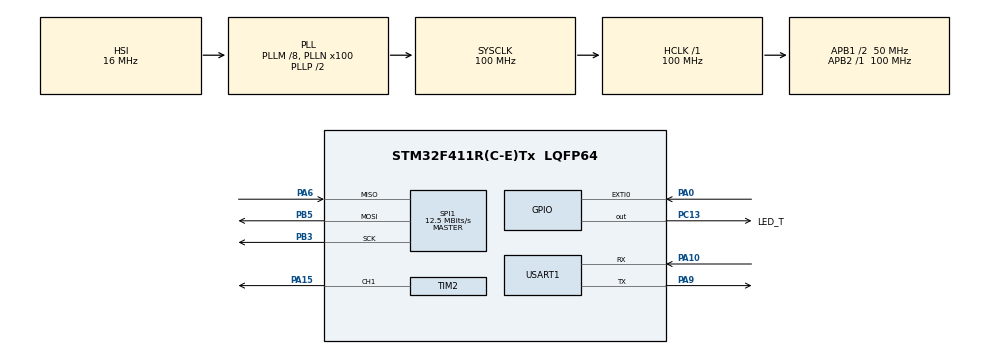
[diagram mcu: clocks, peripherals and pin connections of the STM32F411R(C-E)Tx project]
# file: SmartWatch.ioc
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Dma.Request0=USART1_RX
Dma.Request1=SPI1_TX
Dma.SPI1_TX.1.Direction=DMA_MEMORY_TO_PERIPH
Dma.SPI1_TX.1.FIFOMode=DMA_FIFOMODE_DISABLE
Dma.SPI1_TX.1.Instance=DMA2_Stream3
Dma.SPI1_TX.1.MemDataAlignment=DMA_MDATAALIGN_BYTE
Dma.SPI1_TX.1.MemInc=DMA_MINC_ENABLE
Dma.SPI1_TX.1.Mode=DMA_NORMAL
Dma.SPI1_TX.1.PeriphDataAlignment=DMA_PDATAALIGN_BYTE
Dma.SPI1_TX.1.PeriphInc=DMA_PINC_DISABLE
Dma.SPI1_TX.1.Priority=DMA_PRIORITY_HIGH
Dma.USART1_RX.0.Direction=DMA_PERIPH_TO_MEMORY
Dma.USART1_RX.0.FIFOMode=DMA_FIFOMODE_DISABLE
Dma.USART1_RX.0.Instance=DMA2_Stream2
Dma.USART1_RX.0.MemDataAlignment=DMA_MDATAALIGN_BYTE
Dma.USART1_RX.0.MemInc=DMA_MINC_ENABLE
Dma.USART1_RX.0.Mode=DMA_NORMAL
Dma.USART1_RX.0.PeriphDataAlignment=DMA_PDATAALIGN_BYTE
Dma.USART1_RX.0.PeriphInc=DMA_PINC_DISABLE
Dma.USART1_RX.0.Priority=DMA_PRIORITY_LOW
FREERTOS.Tasks01=defaultTask,24,1024,StartDefaultTask,Default,NULL,Dynamic,NULL,NULL
Mcu.Family=STM32F4
Mcu.Name=STM32F411R(C-E)Tx
Mcu.Package=LQFP64
NVIC.DMA2_Stream2_IRQn=true\:5\:0\:false\:false\:true\:true\:false\:true\:true
NVIC.DMA2_Stream3_IRQn=true\:5\:0\:false\:false\:true\:true\:false\:true\:true
NVIC.EXTI0_IRQn=true\:5\:0\:false\:false\:true\:true\:true\:true\:true
NVIC.PriorityGroup=NVIC_PRIORITYGROUP_4
NVIC.SPI1_IRQn=true\:5\:0\:false\:false\:true\:true\:true\:true\:true
NVIC.TIM1_TRG_COM_TIM11_IRQn=true\:5\:0\:false\:false\:true\:true\:true\:true\:true
NVIC.TIM1_UP_TIM10_IRQn=true\:15\:0\:false\:false\:true\:false\:false\:true\:true
NVIC.TimeBase=TIM1_UP_TIM10_IRQn
NVIC.TimeBaseIP=TIM10
NVIC.USART1_IRQn=true\:5\:0\:false\:false\:true\:true\:true\:true\:true
PA0-WKUP.GPIO_ModeDefaultEXTI=GPIO_MODE_IT_FALLING
PA0-WKUP.GPIO_PuPd=GPIO_PULLUP
PA0-WKUP.Signal=GPXTI0
PA10.Mode=Asynchronous
PA10.Signal=USART1_RX
PA13.Mode=Serial_Wire
PA13.Signal=SYS_JTMS-SWDIO
PA14.Mode=Serial_Wire
PA14.Signal=SYS_JTCK-SWCLK
PA15.Signal=S_TIM2_CH1_ETR
PA6.Mode=Full_Duplex_Master
PA6.Signal=SPI1_MISO
PA9.Mode=Asynchronous
PA9.Signal=USART1_TX
PB3.Mode=Full_Duplex_Master
PB3.Signal=SPI1_SCK
PB5.Mode=Full_Duplex_Master
PB5.Signal=SPI1_MOSI
PC13-ANTI_TAMP.GPIO_Label=LED_T
PC13-ANTI_TAMP.Signal=GPIO_Output
PC14-OSC32_IN.Mode=LSE-External-Oscillator
PC14-OSC32_IN.Signal=RCC_OSC32_IN
PC15-OSC32_OUT.Mode=LSE-External-Oscillator
PC15-OSC32_OUT.Signal=RCC_OSC32_OUT
PH0\ -\ OSC_IN.Mode=HSE-External-Oscillator
PH0\ -\ OSC_IN.Signal=RCC_OSC_IN
PH1\ -\ OSC_OUT.Mode=HSE-External-Oscillator
PH1\ -\ OSC_OUT.Signal=RCC_OSC_OUT
ProjectManager.HeapSize=0x200
ProjectManager.StackSize=0x400
ProjectManager.TargetToolchain=MDK-ARM V5.32
RCC.48MHZClocksFreq_Value=50000000
RCC.AHBFreq_Value=100000000
RCC.APB1CLKDivider=RCC_HCLK_DIV2
RCC.APB1Freq_Value=50000000
RCC.APB1TimFreq_Value=100000000
RCC.APB2Freq_Value=100000000
RCC.APB2TimFreq_Value=100000000
RCC.CortexFreq_Value=100000000
RCC.HCLKFreq_Value=100000000
RCC.HSE_VALUE=25000000
RCC.HSI_VALUE=16000000
RCC.PLLM=8
RCC.PLLN=100
RCC.RCC_RTC_Clock_Source=RCC_RTCCLKSOURCE_LSE
RCC.RCC_RTC_Clock_SourceVirtual=RCC_RTCCLKSOURCE_LSE
RCC.SYSCLKFreq_VALUE=100000000
RCC.SYSCLKSource=RCC_SYSCLKSOURCE_PLLCLK
RCC.VCOOutputFreq_Value=200000000
SH.S_TIM2_CH1_ETR.0=TIM2_CH1,PWM Generation1 CH1
SPI1.BaudRatePrescaler=SPI_BAUDRATEPRESCALER_8
SPI1.CalculateBaudRate=12.5 MBits/s
SPI1.Direction=SPI_DIRECTION_2LINES
SPI1.Mode=SPI_MODE_MASTER
SPI1.VirtualType=VM_MASTER
TIM11.Period=999
TIM11.Prescaler=99
TIM2.Channel-PWM\ Generation1\ CH1=TIM_CHANNEL_1
TIM2.Period=999
TIM2.Prescaler=99
USART1.VirtualMode=VM_ASYNC
VP_FREERTOS_VS_CMSIS_V2.Mode=CMSIS_V2
VP_RTC_VS_RTC_Activate.Mode=RTC_Enabled
VP_SYS_VS_tim10.Mode=TIM10
VP_TIM11_VS_ClockSourceINT.Mode=Enable_Timer
board=custom

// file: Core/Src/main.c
/* USER CODE BEGIN Header */
/**
  ******************************************************************************
  * @file           : main.c
  * @brief          : Main program body
  ******************************************************************************
  * @attention
  *
  * Copyright (c) 2026 STMicroelectronics.
  * All rights reserved.
  *
  * This software is licensed under terms that can be found in the LICENSE file
  * in the root directory of this software component.
  * If no LICENSE file comes with this software, it is provided AS-IS.
  *
  ******************************************************************************
  */
/* USER CODE END Header */
#include "main.h"
#include "cmsis_os.h"
#include "dma.h"
#include "rtc.h"
#include "spi.h"
#include "tim.h"
#include "usart.h"
#include "gpio.h"

/* USER CODE BEGIN Includes */
#include "delay.h"
#include "lcd.h"
#include "lcd_init.h"
/* USER CODE END Includes */

void SystemClock_Config(void);
void MX_FREERTOS_Init(void);

int main(void)
{

  /* MCU Configuration--------------------------------------------------------*/

  /* Reset of all peripherals, Initializes the Flash interface and the Systick. */
  HAL_Init();

  /* Configure the system clock */
  SystemClock_Config();

  /* Initialize all configured peripherals */
  MX_GPIO_Init();
  MX_DMA_Init();
  MX_RTC_Init();
  MX_USART1_UART_Init();
  MX_TIM11_Init();
  MX_SPI1_Init();
  MX_TIM2_Init();
  /* USER CODE BEGIN 2 */

  delay_init();

  /* USER CODE END 2 */

  /* Init scheduler */
  osKernelInitialize();  /* Call init function for freertos objects (in cmsis_os2.c) */
  MX_FREERTOS_Init();

  /* Start scheduler */
  osKernelStart();

  /* We should never get here as control is now taken by the scheduler */

  /* Infinite loop */
  while (1)
  {

  }
}

void SystemClock_Config(void)
{
  RCC_OscInitTypeDef RCC_OscInitStruct = {0};
  RCC_ClkInitTypeDef RCC_ClkInitStruct = {0};

  /** Configure the main internal regulator output voltage
  */
  __HAL_RCC_PWR_CLK_ENABLE();
  __HAL_PWR_VOLTAGESCALING_CONFIG(PWR_REGULATOR_VOLTAGE_SCALE1);

  /** Initializes the RCC Oscillators according to the specified parameters
  * in the RCC_OscInitTypeDef structure.
  */
  RCC_OscInitStruct.OscillatorType = RCC_OSCILLATORTYPE_HSI|RCC_OSCILLATORTYPE_LSE;
  RCC_OscInitStruct.LSEState = RCC_LSE_ON;
  RCC_OscInitStruct.HSIState = RCC_HSI_ON;
  RCC_OscInitStruct.HSICalibrationValue = RCC_HSICALIBRATION_DEFAULT;
  RCC_OscInitStruct.PLL.PLLState = RCC_PLL_ON;
  RCC_OscInitStruct.PLL.PLLSource = RCC_PLLSOURCE_HSI;
  RCC_OscInitStruct.PLL.PLLM = 8;
  RCC_OscInitStruct.PLL.PLLN = 100;
  RCC_OscInitStruct.PLL.PLLP = RCC_PLLP_DIV2;
  RCC_OscInitStruct.PLL.PLLQ = 4;
  if (HAL_RCC_OscConfig(&RCC_OscInitStruct) != HAL_OK)
  {
    Error_Handler();
  }

  /** Initializes the CPU, AHB and APB buses clocks
  */
  RCC_ClkInitStruct.ClockType = RCC_CLOCKTYPE_HCLK|RCC_CLOCKTYPE_SYSCLK
                              |RCC_CLOCKTYPE_PCLK1|RCC_CLOCKTYPE_PCLK2;
  RCC_ClkInitStruct.SYSCLKSource = RCC_SYSCLKSOURCE_PLLCLK;
  RCC_ClkInitStruct.AHBCLKDivider = RCC_SYSCLK_DIV1;
  RCC_ClkInitStruct.APB1CLKDivider = RCC_HCLK_DIV2;
  RCC_ClkInitStruct.APB2CLKDivider = RCC_HCLK_DIV1;

  if (HAL_RCC_ClockConfig(&RCC_ClkInitStruct, FLASH_LATENCY_3) != HAL_OK)
  {
    Error_Handler();
  }
}

void HAL_TIM_PeriodElapsedCallback(TIM_HandleTypeDef *htim)
{
  if (htim->Instance == TIM10)
  {
    HAL_IncTick();
  }
}

void Error_Handler(void)
{
  __disable_irq();
  while (1)
  {
  }
}

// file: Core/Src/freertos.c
/* USER CODE BEGIN Header */
/**
  ******************************************************************************
  * File Name          : freertos.c
  * Description        : Code for freertos applications
  ******************************************************************************
  * @attention
  *
  * Copyright (c) 2026 STMicroelectronics.
  * All rights reserved.
  *
  * This software is licensed under terms that can be found in the LICENSE file
  * in the root directory of this software component.
  * If no LICENSE file comes with this software, it is provided AS-IS.
  *
  ******************************************************************************
  */
/* USER CODE END Header */

#include "FreeRTOS.h"
#include "task.h"
#include "main.h"
#include "cmsis_os.h"

/* USER CODE BEGIN Includes */
#include "lcd_init.h"
#include "lv_port_disp.h"
#include "user_TasksInit.h"
/* USER CODE END Includes */

/* Definitions for defaultTask */
osThreadId_t defaultTaskHandle;
const osThreadAttr_t defaultTask_attributes = {
  .name = "defaultTask",
  .stack_size = 1024 * 4,
  .priority = (osPriority_t) osPriorityNormal,
};

void StartDefaultTask(void *argument);

void MX_FREERTOS_Init(void); /* (MISRA C 2004 rule 8.1) */

void MX_FREERTOS_Init(void) {
  /* USER CODE BEGIN Init */
  User_Tasks_Init();

  /* USER CODE END Init */

  /* Create the thread(s) */
  /* creation of defaultTask */
  defaultTaskHandle = osThreadNew(StartDefaultTask, NULL, &defaultTask_attributes);

  /* USER CODE BEGIN RTOS_THREADS */

  /* 添加任务*/

  /* add threads, ... */
  /* USER CODE END RTOS_THREADS */

}

void StartDefaultTask(void *argument)
{
  /* USER CODE BEGIN StartDefaultTask */
        /* 创建表盘 */

  /* Infinite loop */
  for(;;)
  {
    osDelay(500);
  }
  /* USER CODE END StartDefaultTask */
}
